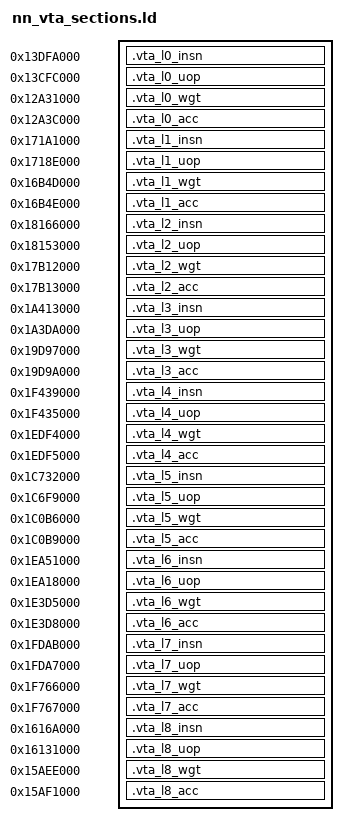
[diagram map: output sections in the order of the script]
/* Auto-generated by the VTA baremetal codegen - DO NOT EDIT        */
/* VTA static model data linker fragment                             */
/*                                                                   */
/* Include this file inside the platform linker script generated.                    */
/* Example (in your lscript.ld):           */
/*   INCLUDE ../gen/nn_vta_sections.ld                                */

SECTIONS {
.vta_l0_insn 0x13DFA000 : { KEEP(*(.vta_l0_insn)) }
.vta_l0_uop 0x13CFC000 : { KEEP(*(.vta_l0_uop)) }
.vta_l0_wgt 0x12A31000 : { KEEP(*(.vta_l0_wgt)) }
.vta_l0_acc 0x12A3C000 : { KEEP(*(.vta_l0_acc)) }
.vta_l1_insn 0x171A1000 : { KEEP(*(.vta_l1_insn)) }
.vta_l1_uop 0x1718E000 : { KEEP(*(.vta_l1_uop)) }
.vta_l1_wgt 0x16B4D000 : { KEEP(*(.vta_l1_wgt)) }
.vta_l1_acc 0x16B4E000 : { KEEP(*(.vta_l1_acc)) }
.vta_l2_insn 0x18166000 : { KEEP(*(.vta_l2_insn)) }
.vta_l2_uop 0x18153000 : { KEEP(*(.vta_l2_uop)) }
.vta_l2_wgt 0x17B12000 : { KEEP(*(.vta_l2_wgt)) }
.vta_l2_acc 0x17B13000 : { KEEP(*(.vta_l2_acc)) }
.vta_l3_insn 0x1A413000 : { KEEP(*(.vta_l3_insn)) }
.vta_l3_uop 0x1A3DA000 : { KEEP(*(.vta_l3_uop)) }
.vta_l3_wgt 0x19D97000 : { KEEP(*(.vta_l3_wgt)) }
.vta_l3_acc 0x19D9A000 : { KEEP(*(.vta_l3_acc)) }
.vta_l4_insn 0x1F439000 : { KEEP(*(.vta_l4_insn)) }
.vta_l4_uop 0x1F435000 : { KEEP(*(.vta_l4_uop)) }
.vta_l4_wgt 0x1EDF4000 : { KEEP(*(.vta_l4_wgt)) }
.vta_l4_acc 0x1EDF5000 : { KEEP(*(.vta_l4_acc)) }
.vta_l5_insn 0x1C732000 : { KEEP(*(.vta_l5_insn)) }
.vta_l5_uop 0x1C6F9000 : { KEEP(*(.vta_l5_uop)) }
.vta_l5_wgt 0x1C0B6000 : { KEEP(*(.vta_l5_wgt)) }
.vta_l5_acc 0x1C0B9000 : { KEEP(*(.vta_l5_acc)) }
.vta_l6_insn 0x1EA51000 : { KEEP(*(.vta_l6_insn)) }
.vta_l6_uop 0x1EA18000 : { KEEP(*(.vta_l6_uop)) }
.vta_l6_wgt 0x1E3D5000 : { KEEP(*(.vta_l6_wgt)) }
.vta_l6_acc 0x1E3D8000 : { KEEP(*(.vta_l6_acc)) }
.vta_l7_insn 0x1FDAB000 : { KEEP(*(.vta_l7_insn)) }
.vta_l7_uop 0x1FDA7000 : { KEEP(*(.vta_l7_uop)) }
.vta_l7_wgt 0x1F766000 : { KEEP(*(.vta_l7_wgt)) }
.vta_l7_acc 0x1F767000 : { KEEP(*(.vta_l7_acc)) }
.vta_l8_insn 0x1616A000 : { KEEP(*(.vta_l8_insn)) }
.vta_l8_uop 0x16131000 : { KEEP(*(.vta_l8_uop)) }
.vta_l8_wgt 0x15AEE000 : { KEEP(*(.vta_l8_wgt)) }
.vta_l8_acc 0x15AF1000 : { KEEP(*(.vta_l8_acc)) }
}
